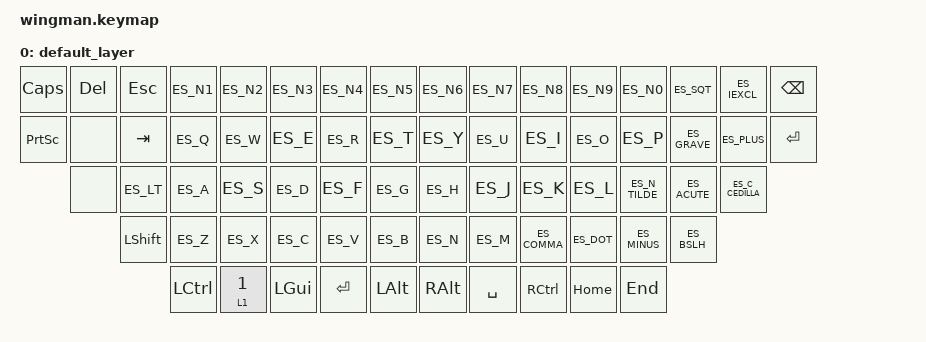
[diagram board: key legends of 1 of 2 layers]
/*
 * Copyright (c) 2020 The ZMK Contributors
 *
 * SPDX-License-Identifier: MIT
 */

#include <locale/keys_es.h>
#include <behaviors.dtsi>
#include <dt-bindings/zmk/keys.h>
#include <dt-bindings/zmk/bt.h>
#include <dt-bindings/zmk/backlight.h>

/ {
        keymap {
                compatible = "zmk,keymap";

                default_layer {
// -----------------------------------------------------------------------------------------
// | CAPS | DEL  | ESC  |  1  |  2  |  3  |  4  |  5  |             |  6  |  7   |  8  |  9  |  0  |  '  |  ¡  | BSPC |
// |  SS  | NONE | TAB  |  Q  |  W  |  E  |  R  |  T  |             |  Y  |  U   |  I  |  O  |  P  |  `  |  +  | ENT  |
//        | NONE | <    |  A  |  S  |  D  |  F  |  G  |             |  H  |  J   |  K  |  L  |  Ñ  |  ´  |  Ç  |
//               | SHFT |  Z  |  X  |  C  |  V  |  B  |             |  N  |  M   |  ,  |  .  |  -  |  \  |
//                      | CTRL| LWR | GUI | ENT | ALT |             | ALT | SPC  | CTRL| HOME| END |
                                                bindings = <
&kp CAPS           &kp DEL   &kp ESC   &kp ES_N1   &kp ES_N2   &kp ES_N3   &kp ES_N4   &kp ES_N5         &kp ES_N6   &kp ES_N7   &kp ES_N8      &kp ES_N9    &kp ES_N0      &kp ES_SQT    &kp ES_IEXCL    &kp BSPC
&kp PRINTSCREEN    &none     &kp TAB   &kp ES_Q    &kp ES_W    &kp ES_E    &kp ES_R    &kp ES_T          &kp ES_Y    &kp ES_U    &kp ES_I       &kp ES_O     &kp ES_P       &kp ES_GRAVE  &kp ES_PLUS     &kp RET
                   &none     &kp ES_LT &kp ES_A    &kp ES_S    &kp ES_D    &kp ES_F    &kp ES_G          &kp ES_H    &kp ES_J    &kp ES_K       &kp ES_L     &kp ES_N_TILDE &kp ES_ACUTE  &kp ES_C_CEDILLA
                             &kp LSHFT &kp ES_Z    &kp ES_X    &kp ES_C    &kp ES_V    &kp ES_B          &kp ES_N    &kp ES_M    &kp ES_COMMA   &kp ES_DOT   &kp ES_MINUS   &kp ES_BSLH
                                       &kp LCTRL   &lt 1 1     &kp LGUI    &kp RET     &kp LALT          &kp RALT    &kp SPACE   &kp RCTRL      &kp HOME     &kp END
                        >;
                };
                lower_layer {
// -----------------------------------------------------------------------------------------
// |    |      | F1   | F2   | F3   | F4  | F5  | F6  |             | F7  | F8  | F9  | F10 | F11 | F12 |     |      |
// |    |      | MUTE | VOL- | VOL+ |BRHT-|BRHT+|     |             |     | UP  |     |     |     |     |     |      |
//      |      | RGBT | BL+  | BL-  |     |     |     |             | LEFT|DOWN |RIGHT|     |     |     |     |
//             |      |      |      |     |     |     |             |     |     |     |     |     |     |
//                    |      |      |     |     |     |             |     |     |     |     |     |
                                                bindings = <
   &none      &none      &kp F1        &kp F2            &kp F3          &kp F4            &kp F5        &kp F6           &kp F7    &kp F8    &kp F9     &kp F10   &kp F11   &kp F12   &none   &none
   &none      &none      &kp C_MUTE    &kp C_VOL_DOWN    &kp C_VOL_UP    &kp C_BRI_DOWN    &kp C_BRI_UP  &none            &none     &kp UP    &none      &none     &none     &none     &none   &none
                         &bl BL_TOG    &bl BL_INC        &bl BL_DEC      &none             &none         &none            &kp LEFT  &kp DOWN  &kp RIGHT  &none     &none     &none     &none
                                       &none             &none           &none             &none         &none            &none     &none     &none      &none     &none     &none
                                                         &none           &none             &none         &none            &none     &none     &none      &none    &none
                                                >;
                        >;
                };
        };
};
